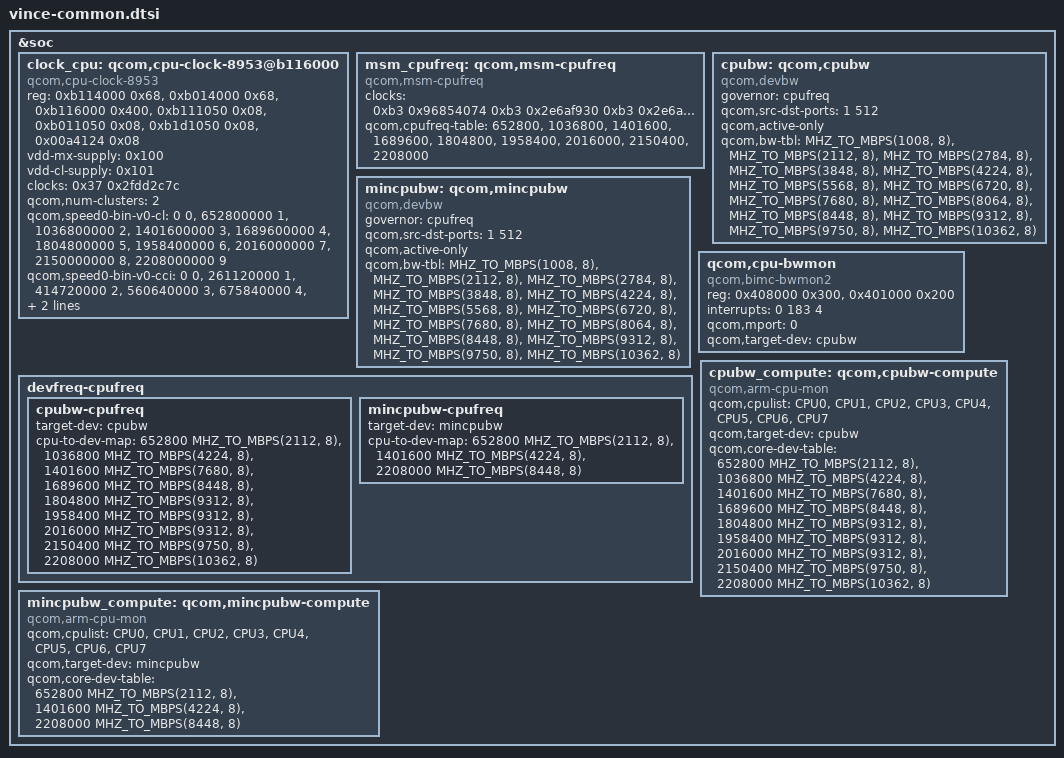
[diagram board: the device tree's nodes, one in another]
/*
 * Copyright (c) 2015-2016, 2019, The Linux Foundation. All rights reserved.
 *
 * This program is free software; you can redistribute it and/or modify
 * it under the terms of the GNU General Public License version 2 and
 * only version 2 as published by the Free Software Foundation.
 *
 * This program is distributed in the hope that it will be useful,
 * but WITHOUT ANY WARRANTY; without even the implied warranty of
 * MERCHANTABILITY or FITNESS FOR A PARTICULAR PURPOSE.  See the
 * GNU General Public License for more details.
 */

#define MHZ_TO_MBPS(mhz, w) ((mhz * 1000000 * w) / (10240 * 1024))

&soc {

	/delete-node/ qcom,cpu-clock-8953@b116000;
	/delete-node/ qcom,msm-cpufreq;
	/delete-node/ qcom,cpubw;
	/delete-node/ qcom,mincpubw;
	/delete-node/ qcom,cpu-bwmon;
	/delete-node/ devfreq-cpufreq;
	/delete-node/ qcom,cpubw-compute;
	/delete-node/ qcom,mincpubw-compute;

	clock_cpu: qcom,cpu-clock-8953@b116000 {
		compatible = "qcom,cpu-clock-8953";
		reg =	 <0xb114000  0x68>,
			 <0xb014000  0x68>,
			 <0xb116000  0x400>,
			 <0xb111050  0x08>,
			 <0xb011050  0x08>,
			 <0xb1d1050  0x08>,
			 <0x00a4124  0x08>;
		reg-names = "rcgwr-c0-base", "rcgwr-c1-base",
				"c0-pll", "c0-mux", "c1-mux",
				"cci-mux", "efuse";
		vdd-mx-supply = <0x100>;
		vdd-cl-supply = <0x101>;
		clocks = <0x37 0x2fdd2c7c>;
		clock-names = "xo_a";
		qcom,num-clusters = <2>;
		qcom,speed0-bin-v0-cl =
			<          0 0>,
			<  652800000 1>,
			< 1036800000 2>,
			< 1401600000 3>,
			< 1689600000 4>,
			< 1804800000 5>,
			< 1958400000 6>,
			< 2016000000 7>,
			< 2150000000 8>,
			< 2208000000 9>;
		qcom,speed0-bin-v0-cci =
			<          0 0>,
			<  261120000 1>,
			<  414720000 2>,
			<  560640000 3>,
			<  675840000 4>,
			<  721920000 5>,
			<  783360000 6>,
			<  806400000 7>,
			<  860160000 8>,
			<  883200000 9>;
		#clock-cells = <1>;
	 };

	msm_cpufreq: qcom,msm-cpufreq {
		compatible = "qcom,msm-cpufreq";
		clock-names = "l2_clk", "cpu0_clk", "cpu1_clk", "cpu2_clk",
				"cpu3_clk", "cpu4_clk", "cpu5_clk",
				"cpu6_clk", "cpu7_clk", "cpu8_clk",
				"cpu9_clk"; 
		clocks = <0xb3 0x96854074 0xb3 0x2e6af930 0xb3 0x2e6af930 0xb3 0x2e6af930 0xb3 0x2e6af930 0xb3 0x2e6af930 0xb3 0x2e6af930 0xb3 0x2e6af930 0xb3 0x2e6af930 0xb3 0x2e6af930 0xb3 0x2e6af930>;

		qcom,cpufreq-table =
			 <  652800 >,
			 < 1036800 >,
			 < 1401600 >,
			 < 1689600 >,
			 < 1804800 >,
			 < 1958400 >,
			 < 2016000 >,
			 < 2150400 >,
			 < 2208000 >;
	};

	cpubw: qcom,cpubw {
		compatible = "qcom,devbw";
		governor = "cpufreq";
		qcom,src-dst-ports = <1 512>;
		qcom,active-only;
		qcom,bw-tbl =
			< MHZ_TO_MBPS(1008, 8) /*  769  100.8  MHz */ >,
                        < MHZ_TO_MBPS(2112, 8) /* 1611  211.2  MHz */ >,     /*Low SVS*/
                        < MHZ_TO_MBPS(2784, 8) /* 2124  278.4  MHz */ >,
                        < MHZ_TO_MBPS(3848, 8) /* 2935  384.8   MHz */ >,
                        < MHZ_TO_MBPS(4224, 8) /* 3222  422.4  MHz */ >,     /* SVS */
                        < MHZ_TO_MBPS(5568, 8) /* 4248  556.8  MHz */ >,
                        < MHZ_TO_MBPS(6720, 8) /* 5126  672    MHz */ >,
                        < MHZ_TO_MBPS(7680, 8) /* 5859  768    MHz */ >,     /* SVS+  */
                        < MHZ_TO_MBPS(8064, 8) /* 6152  806.4  MHz */ >,
                        < MHZ_TO_MBPS(8448, 8) /* 6445  844.8  MHz */ >,     /* NOM   */
                        < MHZ_TO_MBPS(9312, 8) /* 7104  931.2  MHz */ >,     /* TURBO */
			< MHZ_TO_MBPS(9750, 8) /* 7438  975    MHz */ >,
			< MHZ_TO_MBPS(10362, 8) /* 7905 1036.2 MHz */ >;
	};

	mincpubw: qcom,mincpubw {
		compatible = "qcom,devbw";
		governor = "cpufreq";
		qcom,src-dst-ports = <1 512>;
		qcom,active-only;
		qcom,bw-tbl =
			< MHZ_TO_MBPS(1008, 8) /*  769  100.8  MHz */ >,
                        < MHZ_TO_MBPS(2112, 8) /* 1611  211.2  MHz */ >,     /*Low SVS*/
                        < MHZ_TO_MBPS(2784, 8) /* 2124  278.4  MHz */ >,
                        < MHZ_TO_MBPS(3848, 8) /* 2935  384.8   MHz */ >,
                        < MHZ_TO_MBPS(4224, 8) /* 3222  422.4  MHz */ >,     /* SVS */
                        < MHZ_TO_MBPS(5568, 8) /* 4248  556.8  MHz */ >,
                        < MHZ_TO_MBPS(6720, 8) /* 5126  672    MHz */ >,
                        < MHZ_TO_MBPS(7680, 8) /* 5859  768    MHz */ >,     /* SVS+  */
                        < MHZ_TO_MBPS(8064, 8) /* 6152  806.4  MHz */ >,
                        < MHZ_TO_MBPS(8448, 8) /* 6445  844.8  MHz */ >,     /* NOM   */
                        < MHZ_TO_MBPS(9312, 8) /* 7104  931.2  MHz */ >,     /* TURBO */
			< MHZ_TO_MBPS(9750, 8) /* 7438  975    MHz */ >,
			< MHZ_TO_MBPS(10362, 8) /* 7905 1036.2 MHz */ >;
	};

	qcom,cpu-bwmon {
		compatible = "qcom,bimc-bwmon2";
		reg = <0x408000 0x300>, <0x401000 0x200>;
		reg-names = "base", "global_base";
		interrupts = <0 183 4>;
		qcom,mport = <0>;
		qcom,target-dev = <&cpubw>;
	};

	devfreq-cpufreq {
		cpubw-cpufreq {
		target-dev = <&cpubw>;
		cpu-to-dev-map =
			 <  652800  MHZ_TO_MBPS(2112, 8) >,
			 < 1036800  MHZ_TO_MBPS(4224, 8) >,
			 < 1401600  MHZ_TO_MBPS(7680, 8) >,
			 < 1689600  MHZ_TO_MBPS(8448, 8) >,
			 < 1804800  MHZ_TO_MBPS(9312, 8) >,
			 < 1958400  MHZ_TO_MBPS(9312, 8) >,
			 < 2016000  MHZ_TO_MBPS(9312, 8) >,
			 < 2150400  MHZ_TO_MBPS(9750, 8) >,
			 < 2208000  MHZ_TO_MBPS(10362, 8) >;
		};

		mincpubw-cpufreq {
			target-dev = <&mincpubw>;
			cpu-to-dev-map =
				<  652800 MHZ_TO_MBPS(2112, 8) >,
				< 1401600 MHZ_TO_MBPS(4224, 8) >,
				< 2208000 MHZ_TO_MBPS(8448, 8) >;
		};
	};

	cpubw_compute: qcom,cpubw-compute {
		compatible = "qcom,arm-cpu-mon";
		qcom,cpulist = < &CPU0 &CPU1 &CPU2 &CPU3
				&CPU4 &CPU5 &CPU6 &CPU7 >;
		qcom,target-dev = <&cpubw>;
		qcom,core-dev-table =
			 <  652800  MHZ_TO_MBPS(2112, 8) >,
			 < 1036800  MHZ_TO_MBPS(4224, 8) >,
			 < 1401600  MHZ_TO_MBPS(7680, 8) >,
			 < 1689600  MHZ_TO_MBPS(8448, 8) >,
			 < 1804800  MHZ_TO_MBPS(9312, 8) >,
			 < 1958400  MHZ_TO_MBPS(9312, 8) >,
			 < 2016000  MHZ_TO_MBPS(9312, 8) >,
			 < 2150400  MHZ_TO_MBPS(9750, 8) >,
			 < 2208000  MHZ_TO_MBPS(10362, 8) >;
	};

	mincpubw_compute: qcom,mincpubw-compute {
		compatible = "qcom,arm-cpu-mon";
		qcom,cpulist = < &CPU0 &CPU1 &CPU2 &CPU3
				&CPU4 &CPU5 &CPU6 &CPU7 >;
		qcom,target-dev = <&mincpubw>;
		qcom,core-dev-table =
				<  652800 MHZ_TO_MBPS(2112, 8) >,
				< 1401600 MHZ_TO_MBPS(4224, 8) >,
				< 2208000 MHZ_TO_MBPS(8448, 8) >;
	};
};
